VERSION ""

NS_ :

BS_:

BU_:
VAL_TABLE_ vAction_t 0 "va_Off" 1 "va_On" 2 "va_Reserved" 3 "va_Take_no_action" ;

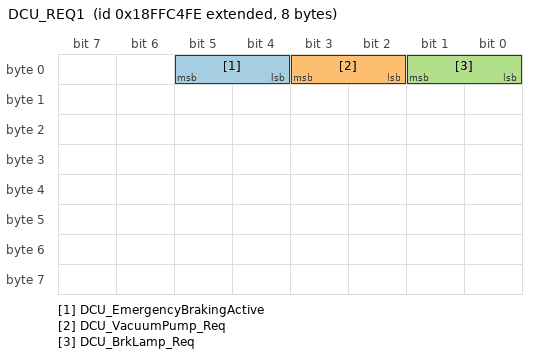
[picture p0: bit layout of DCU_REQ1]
BO_ 2566898942 DCU_REQ1: 8 Vector__XXX
 SG_ DCU_EmergencyBrakingActive : 4|2@1+ (1,0) [0|0] "" Vector__XXX
 SG_ DCU_VacuumPump_Req : 2|2@1+ (1,0) [0|0] "" Vector__XXX
 SG_ DCU_BrkLamp_Req : 0|2@1+ (1,0) [0|0] "" Vector__XXX

BA_DEF_  "BusType" STRING ;
BA_DEF_  "DBName" STRING ;
BA_DEF_ BO_  "GenMsgCycleTime" INT 0 3600000;
BA_DEF_ BO_  "GenMsgILSupport" ENUM  "No","Yes";
BA_DEF_ BO_  "GenMsgRequestable" INT 0 1;
BA_DEF_ BO_  "GenMsgSendType" ENUM  "cyclic","NotUsed","IfActive","NotUsed","NotUsed","NotUsed","NotUsed","NotUsed","noMsgSendType";
BA_DEF_ SG_  "GenSigEVName" STRING ;
BA_DEF_ SG_  "GenSigILSupport" ENUM  "No","Yes";
BA_DEF_ SG_  "GenSigSendType" ENUM  "Cyclic","OnWrite","OnWriteWithRepetition","OnChange","OnChangeWithRepetition","IfActive","IfActiveWithRepetition","NoSigSendType";
BA_DEF_ BU_  "NmStationAddress" INT 0 255;
BA_DEF_  "ProtocolType" STRING ;
BA_DEF_ BO_  "SendOnChange" ENUM  "No","Yes";
BA_DEF_ SG_  "SigType" ENUM  "Default","Range","RangeSigned","ASCII","Discrete","Control","ReferencePGN","DTC","StringDelimiter","StringLength","StringLengthControl";
BA_DEF_ BO_  "VFrameFormat" ENUM  "StandardCAN","ExtendedCAN","reserved","J1939PG";
BA_DEF_DEF_  "BusType" "CAN";
BA_DEF_DEF_  "DBName" "";
BA_DEF_DEF_  "GenMsgCycleTime" 0;
BA_DEF_DEF_  "GenMsgILSupport" "Yes";
BA_DEF_DEF_  "GenMsgRequestable" 1;
BA_DEF_DEF_  "GenMsgSendType" "noMsgSendType";
BA_DEF_DEF_  "GenSigEVName" "Env@Nodename_@Signame";
BA_DEF_DEF_  "GenSigILSupport" "Yes";
BA_DEF_DEF_  "GenSigSendType" "NoSigSendType";
BA_DEF_DEF_  "NmStationAddress" 254;
BA_DEF_DEF_  "ProtocolType" "J1939";
BA_DEF_DEF_  "SendOnChange" "No";
BA_DEF_DEF_  "SigType" "Default";
BA_DEF_DEF_  "VFrameFormat" "J1939PG";
BA_ "DBName" "CHRG_MS3_DCU";
BA_ "SendOnChange" BO_ 2566898942 1;
BA_ "GenMsgCycleTime" BO_ 2566898942 100;
VAL_ 2566898942 DCU_EmergencyBrakingActive 0 "va_Off" 1 "va_On" 2 "va_Reserved" 3 "va_Take_no_action" ;
VAL_ 2566898942 DCU_VacuumPump_Req 0 "va_Off" 1 "va_On" 2 "va_Reserved" 3 "va_Take_no_action" ;
VAL_ 2566898942 DCU_BrkLamp_Req 0 "vBL_Off" 1 "vBL_On" 2 "vBL_ESS" 3 "vBL_NA" ;
